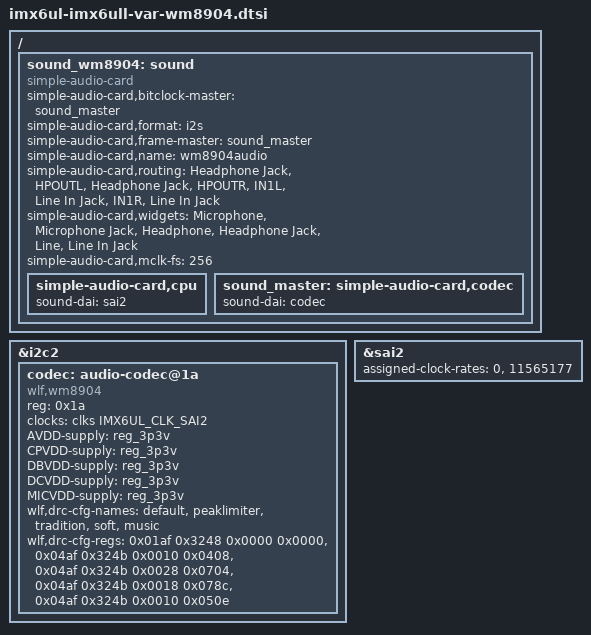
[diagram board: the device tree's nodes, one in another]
// SPDX-License-Identifier: GPL-2.0+
/*
 * Copyright (C) 2026 Variscite Ltd. - https://www.variscite.com
 */

#include "imx6ul-var-som-audio.dtsi"

/ {
	sound_wm8904: sound {
		compatible = "simple-audio-card";
		simple-audio-card,bitclock-master = <&sound_master>;
		simple-audio-card,format = "i2s";
		simple-audio-card,frame-master = <&sound_master>;
		simple-audio-card,name = "wm8904audio";
		simple-audio-card,routing =
			"Headphone Jack", "HPOUTL",
			"Headphone Jack", "HPOUTR",
			"IN1L", "Line In Jack",
			"IN1R", "Line In Jack";
		simple-audio-card,widgets =
			"Microphone", "Microphone Jack",
			"Headphone", "Headphone Jack",
			"Line", "Line In Jack";
		simple-audio-card,mclk-fs = <256>;

		simple-audio-card,cpu {
			sound-dai = <&sai2>;
		};

		sound_master: simple-audio-card,codec {
			sound-dai = <&codec>;
		};
	};
};

&i2c2 {
	codec: audio-codec@1a {
		compatible = "wlf,wm8904";
		reg = <0x1a>;
		#sound-dai-cells = <0>;
		clocks = <&clks IMX6UL_CLK_SAI2>;
		clock-names = "mclk";
		AVDD-supply = <&reg_3p3v>;
		CPVDD-supply = <&reg_3p3v>;
		DBVDD-supply = <&reg_3p3v>;
		DCVDD-supply = <&reg_3p3v>;
		MICVDD-supply = <&reg_3p3v>;
		wlf,drc-cfg-names = "default", "peaklimiter", "tradition",
				    "soft", "music";
		/*
		 * Config registers per name, respectively:
		 * KNEE_IP = 0,   KNEE_OP = 0,     HI_COMP = 1,   LO_COMP = 1
		 * KNEE_IP = -24, KNEE_OP = -6,    HI_COMP = 1/4, LO_COMP = 1
		 * KNEE_IP = -42, KNEE_OP = -3,    HI_COMP = 0,   LO_COMP = 1
		 * KNEE_IP = -45, KNEE_OP = -9,    HI_COMP = 1/8, LO_COMP = 1
		 * KNEE_IP = -30, KNEE_OP = -10.5, HI_COMP = 1/4, LO_COMP = 1
		 */
		wlf,drc-cfg-regs = /bits/ 16 <0x01af 0x3248 0x0000 0x0000>,
				   /bits/ 16 <0x04af 0x324b 0x0010 0x0408>,
				   /bits/ 16 <0x04af 0x324b 0x0028 0x0704>,
				   /bits/ 16 <0x04af 0x324b 0x0018 0x078c>,
				   /bits/ 16 <0x04af 0x324b 0x0010 0x050e>;
	};
};

&sai2 {
	assigned-clock-rates = <0>, <11565177>;
};
